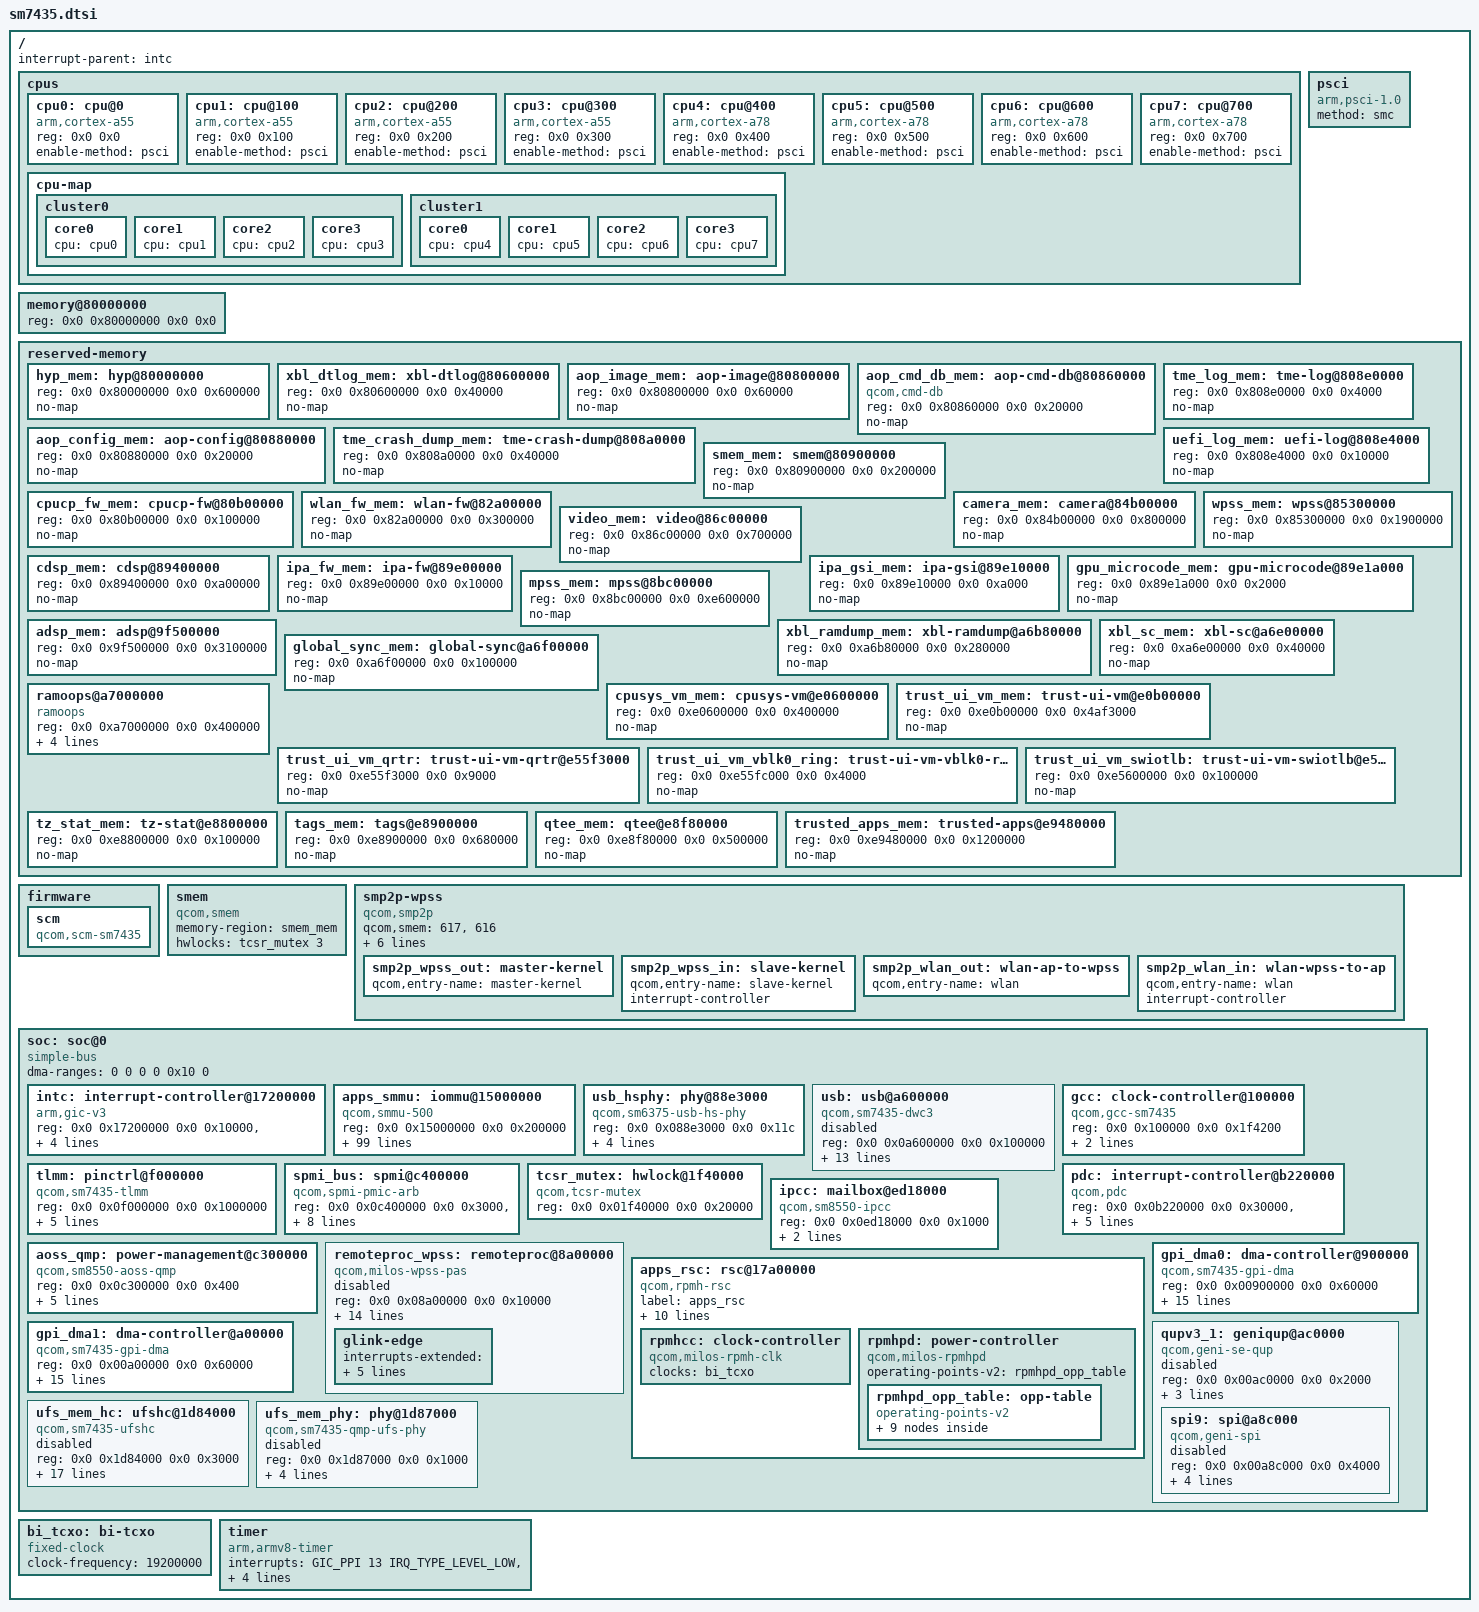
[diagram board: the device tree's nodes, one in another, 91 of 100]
// SPDX-License-Identifier: BSD-3-Clause
/*
 * Qualcomm SM7435 (Snapdragon 7s Gen 2, "parrot") - STAGE 1 skeleton
 *
 * Only what is needed to boot to an initramfs via UEFI:
 * CPUs, PSCI, GICv3, arch timer, reserved memory, ramoops,
 * plus SCM/SMMU, GPI DMA/QUPv3, UFS, USB and SPMI/RPMh (the latter
 * only so that board DTS files can describe PMIC regulators).
 * Values taken from the stock DTB (Mu-Silicium Resources/DTBs/garnet.dts).
 *
 * NOT here yet: display, interconnect, most clocks and pinctrl, ...
 */

#include <dt-bindings/clock/qcom,gcc-sm7435.h>
#include <dt-bindings/clock/qcom,rpmh.h>
#include <dt-bindings/dma/qcom-gpi.h>
#include <dt-bindings/interrupt-controller/arm-gic.h>
#include <dt-bindings/mailbox/qcom-ipcc.h>
#include <dt-bindings/power/qcom,rpmhpd.h>
#include <dt-bindings/soc/qcom,rpmh-rsc.h>

/ {
	interrupt-parent = <&intc>;
	#address-cells = <2>;
	#size-cells = <2>;

	cpus {
		#address-cells = <2>;
		#size-cells = <0>;

		/* 4x Cortex-A55 ("silver") */
		cpu0: cpu@0 {
			device_type = "cpu";
			compatible = "arm,cortex-a55";
			reg = <0x0 0x0>;
			enable-method = "psci";
		};

		cpu1: cpu@100 {
			device_type = "cpu";
			compatible = "arm,cortex-a55";
			reg = <0x0 0x100>;
			enable-method = "psci";
		};

		cpu2: cpu@200 {
			device_type = "cpu";
			compatible = "arm,cortex-a55";
			reg = <0x0 0x200>;
			enable-method = "psci";
		};

		cpu3: cpu@300 {
			device_type = "cpu";
			compatible = "arm,cortex-a55";
			reg = <0x0 0x300>;
			enable-method = "psci";
		};

		/* 4x Cortex-A78 ("gold") */
		cpu4: cpu@400 {
			device_type = "cpu";
			compatible = "arm,cortex-a78";
			reg = <0x0 0x400>;
			enable-method = "psci";
		};

		cpu5: cpu@500 {
			device_type = "cpu";
			compatible = "arm,cortex-a78";
			reg = <0x0 0x500>;
			enable-method = "psci";
		};

		cpu6: cpu@600 {
			device_type = "cpu";
			compatible = "arm,cortex-a78";
			reg = <0x0 0x600>;
			enable-method = "psci";
		};

		cpu7: cpu@700 {
			device_type = "cpu";
			compatible = "arm,cortex-a78";
			reg = <0x0 0x700>;
			enable-method = "psci";
		};

		cpu-map {
			cluster0 {
				core0 { cpu = <&cpu0>; };
				core1 { cpu = <&cpu1>; };
				core2 { cpu = <&cpu2>; };
				core3 { cpu = <&cpu3>; };
			};

			cluster1 {
				core0 { cpu = <&cpu4>; };
				core1 { cpu = <&cpu5>; };
				core2 { cpu = <&cpu6>; };
				core3 { cpu = <&cpu7>; };
			};
		};
	};

	psci {
		compatible = "arm,psci-1.0";
		method = "smc";
	};

	/*
	 * RAM is taken from the UEFI memory map; the stock memory node has
	 * odd, variant-specific ranges. Zero size = ignored by the kernel.
	 */
	memory@80000000 {
		device_type = "memory";
		reg = <0x0 0x80000000 0x0 0x0>;
	};

	reserved-memory {
		#address-cells = <2>;
		#size-cells = <2>;
		ranges;

		hyp_mem: hyp@80000000 {
			reg = <0x0 0x80000000 0x0 0x600000>;
			no-map;
		};

		xbl_dtlog_mem: xbl-dtlog@80600000 {
			reg = <0x0 0x80600000 0x0 0x40000>;
			no-map;
		};

		aop_image_mem: aop-image@80800000 {
			reg = <0x0 0x80800000 0x0 0x60000>;
			no-map;
		};

		aop_cmd_db_mem: aop-cmd-db@80860000 {
			compatible = "qcom,cmd-db";
			reg = <0x0 0x80860000 0x0 0x20000>;
			no-map;
		};

		aop_config_mem: aop-config@80880000 {
			reg = <0x0 0x80880000 0x0 0x20000>;
			no-map;
		};

		tme_crash_dump_mem: tme-crash-dump@808a0000 {
			reg = <0x0 0x808a0000 0x0 0x40000>;
			no-map;
		};

		tme_log_mem: tme-log@808e0000 {
			reg = <0x0 0x808e0000 0x0 0x4000>;
			no-map;
		};

		uefi_log_mem: uefi-log@808e4000 {
			reg = <0x0 0x808e4000 0x0 0x10000>;
			no-map;
		};

		smem_mem: smem@80900000 {
			reg = <0x0 0x80900000 0x0 0x200000>;
			no-map;
		};

		cpucp_fw_mem: cpucp-fw@80b00000 {
			reg = <0x0 0x80b00000 0x0 0x100000>;
			no-map;
		};

		wlan_fw_mem: wlan-fw@82a00000 {
			reg = <0x0 0x82a00000 0x0 0x300000>;
			no-map;
		};

		camera_mem: camera@84b00000 {
			reg = <0x0 0x84b00000 0x0 0x800000>;
			no-map;
		};

		wpss_mem: wpss@85300000 {
			reg = <0x0 0x85300000 0x0 0x1900000>;
			no-map;
		};

		video_mem: video@86c00000 {
			reg = <0x0 0x86c00000 0x0 0x700000>;
			no-map;
		};

		cdsp_mem: cdsp@89400000 {
			reg = <0x0 0x89400000 0x0 0xa00000>;
			no-map;
		};

		ipa_fw_mem: ipa-fw@89e00000 {
			reg = <0x0 0x89e00000 0x0 0x10000>;
			no-map;
		};

		ipa_gsi_mem: ipa-gsi@89e10000 {
			reg = <0x0 0x89e10000 0x0 0xa000>;
			no-map;
		};

		gpu_microcode_mem: gpu-microcode@89e1a000 {
			reg = <0x0 0x89e1a000 0x0 0x2000>;
			no-map;
		};

		mpss_mem: mpss@8bc00000 {
			reg = <0x0 0x8bc00000 0x0 0xe600000>;
			no-map;
		};

		adsp_mem: adsp@9f500000 {
			reg = <0x0 0x9f500000 0x0 0x3100000>;
			no-map;
		};

		xbl_ramdump_mem: xbl-ramdump@a6b80000 {
			reg = <0x0 0xa6b80000 0x0 0x280000>;
			no-map;
		};

		xbl_sc_mem: xbl-sc@a6e00000 {
			reg = <0x0 0xa6e00000 0x0 0x40000>;
			no-map;
		};

		global_sync_mem: global-sync@a6f00000 {
			reg = <0x0 0xa6f00000 0x0 0x100000>;
			no-map;
		};

		/* Debug: survives reboot, read via /sys/fs/pstore */
		ramoops@a7000000 {
			compatible = "ramoops";
			reg = <0x0 0xa7000000 0x0 0x400000>;
			record-size = <0x40000>;
			console-size = <0x200000>;
			pmsg-size = <0x100000>;
			no-map;
		};

		/*
		 * cont_splash 0xb8000000 (0x2b00000) is intentionally NOT listed:
		 * the UEFI GOP framebuffer lives around there and the EFI stub
		 * + simpledrm handle it from the EFI memory map.
		 */

		cpusys_vm_mem: cpusys-vm@e0600000 {
			reg = <0x0 0xe0600000 0x0 0x400000>;
			no-map;
		};

		trust_ui_vm_mem: trust-ui-vm@e0b00000 {
			reg = <0x0 0xe0b00000 0x0 0x4af3000>;
			no-map;
		};

		trust_ui_vm_qrtr: trust-ui-vm-qrtr@e55f3000 {
			reg = <0x0 0xe55f3000 0x0 0x9000>;
			no-map;
		};

		trust_ui_vm_vblk0_ring: trust-ui-vm-vblk0-ring@e55fc000 {
			reg = <0x0 0xe55fc000 0x0 0x4000>;
			no-map;
		};

		trust_ui_vm_swiotlb: trust-ui-vm-swiotlb@e5600000 {
			reg = <0x0 0xe5600000 0x0 0x100000>;
			no-map;
		};

		tz_stat_mem: tz-stat@e8800000 {
			reg = <0x0 0xe8800000 0x0 0x100000>;
			no-map;
		};

		tags_mem: tags@e8900000 {
			reg = <0x0 0xe8900000 0x0 0x680000>;
			no-map;
		};

		qtee_mem: qtee@e8f80000 {
			reg = <0x0 0xe8f80000 0x0 0x500000>;
			no-map;
		};

		trusted_apps_mem: trusted-apps@e9480000 {
			reg = <0x0 0xe9480000 0x0 0x1200000>;
			no-map;
		};
	};

	/*
	 * Secure Channel Manager.  arm-smmu-qcom refuses to finish probing
	 * until qcom_scm_is_available() is true, so without this node the
	 * apps SMMU stays in -EPROBE_DEFER forever and every master that
	 * references it (GPI DMA, QUPv3, UFS, USB) defers as well.
	 * Stock: firmware/qcom_scm, compatible "qcom,scm-v1.1", "qcom,scm".
	 */
	firmware {
		scm: scm {
			compatible = "qcom,scm-sm7435", "qcom,scm";
			#reset-cells = <1>;
		};
	};

	smem {
		compatible = "qcom,smem";
		memory-region = <&smem_mem>;
		hwlocks = <&tcsr_mutex 3>;
	};

	smp2p-wpss {
		compatible = "qcom,smp2p";
		qcom,smem = <617>, <616>;
		interrupts-extended = <&ipcc IPCC_CLIENT_WPSS
					     IPCC_MPROC_SIGNAL_SMP2P
					     IRQ_TYPE_EDGE_RISING>;
		mboxes = <&ipcc IPCC_CLIENT_WPSS IPCC_MPROC_SIGNAL_SMP2P>;

		qcom,local-pid = <0>;
		qcom,remote-pid = <13>;

		smp2p_wpss_out: master-kernel {
			qcom,entry-name = "master-kernel";
			#qcom,smem-state-cells = <1>;
		};

		smp2p_wpss_in: slave-kernel {
			qcom,entry-name = "slave-kernel";
			interrupt-controller;
			#interrupt-cells = <2>;
		};

		/* WLAN handshake with the WPSS-hosted WiFi firmware */
		smp2p_wlan_out: wlan-ap-to-wpss {
			qcom,entry-name = "wlan";
			#qcom,smem-state-cells = <1>;
		};

		smp2p_wlan_in: wlan-wpss-to-ap {
			qcom,entry-name = "wlan";
			interrupt-controller;
			#interrupt-cells = <2>;
		};
	};

	soc: soc@0 {
		compatible = "simple-bus";
		#address-cells = <2>;
		#size-cells = <2>;
		ranges = <0 0 0 0 0x10 0>;
		dma-ranges = <0 0 0 0 0x10 0>;

		intc: interrupt-controller@17200000 {
			compatible = "arm,gic-v3";
			reg = <0x0 0x17200000 0x0 0x10000>,	/* GICD */
			      <0x0 0x17260000 0x0 0x100000>;	/* GICR * 8 */
			#interrupt-cells = <3>;
			interrupt-controller;
			#redistributor-regions = <1>;
			interrupts = <GIC_PPI 9 IRQ_TYPE_LEVEL_LOW>;
		};

		/*
		 * Applications SMMU (ARM MMU-500 with Qualcomm glue).
		 *
		 * The APPS SMMU is left enabled by the bootloader, so every bus
		 * master that is not described here is subject to whatever
		 * translation state the firmware programmed.  Linux must own the
		 * SMMU so that the DMA masters it drives are mapped explicitly;
		 * otherwise the first GPI DMA transaction (SPI9 / touchscreen)
		 * takes an SMMU fault and the SoC resets into crashdump/EDL.
		 *
		 * 0x15000000..0x151fffff covers GR0/GR1, the context banks
		 * (0x15100000+) and the TCU (0x151da000).
		 *
		 * NOTE: this kernel is built with
		 * CONFIG_ARM_SMMU_DISABLE_BYPASS_BY_DEFAULT=y, so streams that
		 * are not described via "iommus" are blocked with a global fault
		 * instead of being bypassed.  Every master that can do DMA must
		 * therefore either be listed here (GPI DMA 0/1, QUPv3 1, UFS,
		 * USB) or keep the "arm-smmu.disable_bypass=0" cmdline option.
		 */
		apps_smmu: iommu@15000000 {
			compatible = "qcom,smmu-500", "arm,mmu-500";
			reg = <0x0 0x15000000 0x0 0x200000>;
			#global-interrupts = <1>;
			#iommu-cells = <2>;
			dma-coherent;
			interrupts = 			     <GIC_SPI 65 IRQ_TYPE_LEVEL_HIGH>,
			     <GIC_SPI 96 IRQ_TYPE_LEVEL_HIGH>,
			     <GIC_SPI 670 IRQ_TYPE_LEVEL_HIGH>,
			     <GIC_SPI 671 IRQ_TYPE_LEVEL_HIGH>,
			     <GIC_SPI 97 IRQ_TYPE_LEVEL_HIGH>,
			     <GIC_SPI 98 IRQ_TYPE_LEVEL_HIGH>,
			     <GIC_SPI 99 IRQ_TYPE_LEVEL_HIGH>,
			     <GIC_SPI 100 IRQ_TYPE_LEVEL_HIGH>,
			     <GIC_SPI 101 IRQ_TYPE_LEVEL_HIGH>,
			     <GIC_SPI 102 IRQ_TYPE_LEVEL_HIGH>,
			     <GIC_SPI 103 IRQ_TYPE_LEVEL_HIGH>,
			     <GIC_SPI 104 IRQ_TYPE_LEVEL_HIGH>,
			     <GIC_SPI 105 IRQ_TYPE_LEVEL_HIGH>,
			     <GIC_SPI 106 IRQ_TYPE_LEVEL_HIGH>,
			     <GIC_SPI 107 IRQ_TYPE_LEVEL_HIGH>,
			     <GIC_SPI 108 IRQ_TYPE_LEVEL_HIGH>,
			     <GIC_SPI 109 IRQ_TYPE_LEVEL_HIGH>,
			     <GIC_SPI 110 IRQ_TYPE_LEVEL_HIGH>,
			     <GIC_SPI 111 IRQ_TYPE_LEVEL_HIGH>,
			     <GIC_SPI 112 IRQ_TYPE_LEVEL_HIGH>,
			     <GIC_SPI 113 IRQ_TYPE_LEVEL_HIGH>,
			     <GIC_SPI 114 IRQ_TYPE_LEVEL_HIGH>,
			     <GIC_SPI 115 IRQ_TYPE_LEVEL_HIGH>,
			     <GIC_SPI 116 IRQ_TYPE_LEVEL_HIGH>,
			     <GIC_SPI 117 IRQ_TYPE_LEVEL_HIGH>,
			     <GIC_SPI 118 IRQ_TYPE_LEVEL_HIGH>,
			     <GIC_SPI 181 IRQ_TYPE_LEVEL_HIGH>,
			     <GIC_SPI 182 IRQ_TYPE_LEVEL_HIGH>,
			     <GIC_SPI 183 IRQ_TYPE_LEVEL_HIGH>,
			     <GIC_SPI 184 IRQ_TYPE_LEVEL_HIGH>,
			     <GIC_SPI 185 IRQ_TYPE_LEVEL_HIGH>,
			     <GIC_SPI 186 IRQ_TYPE_LEVEL_HIGH>,
			     <GIC_SPI 187 IRQ_TYPE_LEVEL_HIGH>,
			     <GIC_SPI 188 IRQ_TYPE_LEVEL_HIGH>,
			     <GIC_SPI 189 IRQ_TYPE_LEVEL_HIGH>,
			     <GIC_SPI 190 IRQ_TYPE_LEVEL_HIGH>,
			     <GIC_SPI 191 IRQ_TYPE_LEVEL_HIGH>,
			     <GIC_SPI 192 IRQ_TYPE_LEVEL_HIGH>,
			     <GIC_SPI 315 IRQ_TYPE_LEVEL_HIGH>,
			     <GIC_SPI 316 IRQ_TYPE_LEVEL_HIGH>,
			     <GIC_SPI 317 IRQ_TYPE_LEVEL_HIGH>,
			     <GIC_SPI 318 IRQ_TYPE_LEVEL_HIGH>,
			     <GIC_SPI 319 IRQ_TYPE_LEVEL_HIGH>,
			     <GIC_SPI 320 IRQ_TYPE_LEVEL_HIGH>,
			     <GIC_SPI 321 IRQ_TYPE_LEVEL_HIGH>,
			     <GIC_SPI 322 IRQ_TYPE_LEVEL_HIGH>,
			     <GIC_SPI 323 IRQ_TYPE_LEVEL_HIGH>,
			     <GIC_SPI 324 IRQ_TYPE_LEVEL_HIGH>,
			     <GIC_SPI 325 IRQ_TYPE_LEVEL_HIGH>,
			     <GIC_SPI 326 IRQ_TYPE_LEVEL_HIGH>,
			     <GIC_SPI 327 IRQ_TYPE_LEVEL_HIGH>,
			     <GIC_SPI 328 IRQ_TYPE_LEVEL_HIGH>,
			     <GIC_SPI 329 IRQ_TYPE_LEVEL_HIGH>,
			     <GIC_SPI 330 IRQ_TYPE_LEVEL_HIGH>,
			     <GIC_SPI 331 IRQ_TYPE_LEVEL_HIGH>,
			     <GIC_SPI 332 IRQ_TYPE_LEVEL_HIGH>,
			     <GIC_SPI 333 IRQ_TYPE_LEVEL_HIGH>,
			     <GIC_SPI 334 IRQ_TYPE_LEVEL_HIGH>,
			     <GIC_SPI 335 IRQ_TYPE_LEVEL_HIGH>,
			     <GIC_SPI 336 IRQ_TYPE_LEVEL_HIGH>,
			     <GIC_SPI 337 IRQ_TYPE_LEVEL_HIGH>,
			     <GIC_SPI 338 IRQ_TYPE_LEVEL_HIGH>,
			     <GIC_SPI 339 IRQ_TYPE_LEVEL_HIGH>,
			     <GIC_SPI 340 IRQ_TYPE_LEVEL_HIGH>,
			     <GIC_SPI 341 IRQ_TYPE_LEVEL_HIGH>,
			     <GIC_SPI 342 IRQ_TYPE_LEVEL_HIGH>,
			     <GIC_SPI 343 IRQ_TYPE_LEVEL_HIGH>,
			     <GIC_SPI 344 IRQ_TYPE_LEVEL_HIGH>,
			     <GIC_SPI 345 IRQ_TYPE_LEVEL_HIGH>,
			     <GIC_SPI 395 IRQ_TYPE_LEVEL_HIGH>,
			     <GIC_SPI 396 IRQ_TYPE_LEVEL_HIGH>,
			     <GIC_SPI 397 IRQ_TYPE_LEVEL_HIGH>,
			     <GIC_SPI 398 IRQ_TYPE_LEVEL_HIGH>,
			     <GIC_SPI 399 IRQ_TYPE_LEVEL_HIGH>,
			     <GIC_SPI 400 IRQ_TYPE_LEVEL_HIGH>,
			     <GIC_SPI 401 IRQ_TYPE_LEVEL_HIGH>,
			     <GIC_SPI 402 IRQ_TYPE_LEVEL_HIGH>,
			     <GIC_SPI 403 IRQ_TYPE_LEVEL_HIGH>,
			     <GIC_SPI 404 IRQ_TYPE_LEVEL_HIGH>,
			     <GIC_SPI 405 IRQ_TYPE_LEVEL_HIGH>,
			     <GIC_SPI 406 IRQ_TYPE_LEVEL_HIGH>,
			     <GIC_SPI 407 IRQ_TYPE_LEVEL_HIGH>,
			     <GIC_SPI 408 IRQ_TYPE_LEVEL_HIGH>,
			     <GIC_SPI 409 IRQ_TYPE_LEVEL_HIGH>,
			     <GIC_SPI 412 IRQ_TYPE_LEVEL_HIGH>,
			     <GIC_SPI 418 IRQ_TYPE_LEVEL_HIGH>,
			     <GIC_SPI 419 IRQ_TYPE_LEVEL_HIGH>,
			     <GIC_SPI 421 IRQ_TYPE_LEVEL_HIGH>,
			     <GIC_SPI 706 IRQ_TYPE_LEVEL_HIGH>,
			     <GIC_SPI 423 IRQ_TYPE_LEVEL_HIGH>,
			     <GIC_SPI 424 IRQ_TYPE_LEVEL_HIGH>,
			     <GIC_SPI 425 IRQ_TYPE_LEVEL_HIGH>,
			     <GIC_SPI 689 IRQ_TYPE_LEVEL_HIGH>,
			     <GIC_SPI 690 IRQ_TYPE_LEVEL_HIGH>,
			     <GIC_SPI 691 IRQ_TYPE_LEVEL_HIGH>,
			     <GIC_SPI 692 IRQ_TYPE_LEVEL_HIGH>,
			     <GIC_SPI 693 IRQ_TYPE_LEVEL_HIGH>;
		};


		/*
		 * USB (stage 2a, EXPERIMENTAL): dwc3 + Qualcomm glue, relying on the
		 * clocks, GDSC and HS PHY that Mu-Silicium UEFI already brought up
		 * (boot with clk_ignore_unused pd_ignore_unused). No GCC/PHY/regulator
		 * drivers exist for this SoC yet, so none are referenced here.
		 * Stock node: ssusb@a600000 (core 0xa600000, qscratch = +0xf8800).
		 */
		/*
		 * HS (femto) PHY, stock hsphy@88e3000.  The supplies (stock:
		 * vdd 0.88 V, vdda18, vdda33) are not described yet: the rails
		 * stay as the bootloader left them.
		 */
		usb_hsphy: phy@88e3000 {
			compatible = "qcom,sm6375-usb-hs-phy",
				     "qcom,usb-snps-hs-7nm-phy";
			reg = <0x0 0x088e3000 0x0 0x11c>;

			clocks = <&gcc GCC_EUSB3_0_CLKREF_EN>;
			clock-names = "ref";
			resets = <&gcc GCC_QUSB2PHY_PRIM_BCR>;

			/* stock qcom,param-override-seq: <value offset> pairs */
			qcom,param-override-seq = <0x67 0x6c 0xcb 0x70 0x14 0x74>;

			#phy-cells = <0>;
		};

		usb: usb@a600000 {
			compatible = "qcom,sm7435-dwc3", "qcom,snps-dwc3";
			reg = <0x0 0x0a600000 0x0 0x100000>;
			interrupts = <GIC_SPI 133 IRQ_TYPE_LEVEL_HIGH>;
			interrupt-names = "dwc_usb3";
			phys = <&usb_hsphy>;
			phy-names = "usb2-phy";
			/* stock: dwc3@a600000 iommus = <&apps_smmu 0x80 0> */
			iommus = <&apps_smmu 0x80 0x0>;
			dma-coherent;

			/*
			 * No phy_type: leave GUSB2PHYCFG.PHYIF/USBTRDTIM at the
			 * hardware default like every other Qualcomm femto-PHY
			 * platform.  Forcing "utmi_wide" is a width mismatch if
			 * the PHY runs 8-bit UTMI+ (reset/chirp still work, data
			 * does not -> -71 on the host).
			 */
			snps,has-lpm-erratum;
			snps,hird-threshold = /bits/ 8 <0x0>;
			snps,is-utmi-l1-suspend;
			snps,usb2-gadget-lpm-disable;
			snps,dis-u1-entry-quirk;
			snps,dis-u2-entry-quirk;
			snps,dis_u2_susphy_quirk;
			snps,dis_u3_susphy_quirk;
			/* stock DT sets this; ep0 DEPCFG times out without it */
			snps,disable-clk-gating;

			status = "disabled";
		};

		/*
		 * Global clock controller (stage 2b).
		 *
		 * Only the clocks needed by the UFS host controller and the QMP
		 * UFS PHY are implemented in drivers/clk/qcom/gcc-sm7435.c so far.
		 * The register offsets are taken from the downstream
		 * "qcom,parrot-gcc" driver.
		 */
		gcc: clock-controller@100000 {
			compatible = "qcom,gcc-sm7435";
			reg = <0x0 0x100000 0x0 0x1f4200>;
			#clock-cells = <1>;
			#reset-cells = <1>;
			#power-domain-cells = <1>;

			clocks = <&bi_tcxo>,
				 <&ufs_mem_phy 0>,
				 <&ufs_mem_phy 1>,
				 <&ufs_mem_phy 2>;
			clock-names = "bi_tcxo",
				      "ufs_phy_rx_symbol_0_clk",
				      "ufs_phy_rx_symbol_1_clk",
				      "ufs_phy_tx_symbol_0_clk";
		};

		tlmm: pinctrl@f000000 {
			compatible = "qcom,sm7435-tlmm";
			reg = <0x0 0x0f000000 0x0 0x1000000>;
			interrupts = <GIC_SPI 208 IRQ_TYPE_LEVEL_HIGH>;
			gpio-controller;
			#gpio-cells = <2>;
			gpio-ranges = <&tlmm 0 0 142>;
			/* TZ owned (fingerprint/secure) lines: 0-3, 38 */
			gpio-reserved-ranges = <0 4>, <38 1>;
			interrupt-controller;
			#interrupt-cells = <2>;
		};

		/*
		 * SPMI bus (PMIC arbiter).  Same register layout as SM8550,
		 * taken from the stock garnet DTB.  Needed for the PM6150L
		 * PMIC GPIOs, which drive the touchscreen's 1.8 V iovdd rail.
		 */
		spmi_bus: spmi@c400000 {
			compatible = "qcom,spmi-pmic-arb";
			reg = <0x0 0x0c400000 0x0 0x3000>,
			      <0x0 0x0c500000 0x0 0x400000>,
			      <0x0 0x0c440000 0x0 0x80000>,
			      <0x0 0x0c4c0000 0x0 0x20000>,
			      <0x0 0x0c42d000 0x0 0x4000>;
			reg-names = "core", "chnls", "obsrvr", "intr", "cnfg";
			interrupt-names = "periph_irq";
			interrupts-extended = <&pdc 1 IRQ_TYPE_LEVEL_HIGH>;
			qcom,ee = <0>;
			qcom,channel = <0>;
			#address-cells = <2>;
			#size-cells = <0>;
			interrupt-controller;
			#interrupt-cells = <4>;
		};

		/*
		 * Wakeup interrupt controller in front of a few GIC SPIs
		 * (SPMI peripheral IRQ, ...).  Values from the stock DTB.
		 */
		pdc: interrupt-controller@b220000 {
			compatible = "qcom,pdc";
			reg = <0x0 0x0b220000 0x0 0x30000>,
			      <0x0 0x174000f0 0x0 0x64>;
			reg-names = "pdc-interrupt-base", "apss-shared-spi-cfg";
			qcom,pdc-ranges = <0 480 94>,
					  <94 609 31>,
					  <125 63 1>,
					  <126 716 12>;
			#interrupt-cells = <2>;
			interrupt-parent = <&intc>;
			interrupt-controller;
		};

		tcsr_mutex: hwlock@1f40000 {
			compatible = "qcom,tcsr-mutex";
			reg = <0x0 0x01f40000 0x0 0x20000>;
			#hwlock-cells = <1>;
		};

		/* stock: qcom,ipcc@ed18000 */
		ipcc: mailbox@ed18000 {
			compatible = "qcom,sm8550-ipcc", "qcom,ipcc";
			reg = <0x0 0x0ed18000 0x0 0x1000>;
			interrupts = <GIC_SPI 229 IRQ_TYPE_LEVEL_HIGH>;
			interrupt-controller;
			#interrupt-cells = <3>;
			#mbox-cells = <2>;
		};

		aoss_qmp: power-management@c300000 {
			compatible = "qcom,sm8550-aoss-qmp", "qcom,aoss-qmp";
			reg = <0x0 0x0c300000 0x0 0x400>;
			interrupt-parent = <&ipcc>;
			interrupts-extended = <&ipcc IPCC_CLIENT_AOP
						     IPCC_MPROC_SIGNAL_GLINK_QMP
						     IRQ_TYPE_EDGE_RISING>;
			mboxes = <&ipcc IPCC_CLIENT_AOP IPCC_MPROC_SIGNAL_GLINK_QMP>;
			#clock-cells = <0>;
		};

		/*
		 * WPSS (Wi-Fi processing subsystem): runs the WiFi firmware.
		 * Stock node: remoteproc-wpss@8a00000, qcom,parrot-wpss-pas.
		 * The PAS data of milos/sc7280 (pas_id 6) is reused.
		 */
		remoteproc_wpss: remoteproc@8a00000 {
			compatible = "qcom,milos-wpss-pas";
			reg = <0x0 0x08a00000 0x0 0x10000>;

			interrupts-extended = <&intc GIC_SPI 587 IRQ_TYPE_EDGE_RISING>,
					      <&smp2p_wpss_in 0 IRQ_TYPE_EDGE_RISING>,
					      <&smp2p_wpss_in 1 IRQ_TYPE_EDGE_RISING>,
					      <&smp2p_wpss_in 2 IRQ_TYPE_EDGE_RISING>,
					      <&smp2p_wpss_in 3 IRQ_TYPE_EDGE_RISING>,
					      <&smp2p_wpss_in 7 IRQ_TYPE_EDGE_RISING>;
			interrupt-names = "wdog",
					  "fatal",
					  "ready",
					  "handover",
					  "stop-ack",
					  "shutdown-ack";

			clocks = <&rpmhcc RPMH_CXO_CLK>;
			clock-names = "xo";

			power-domains = <&rpmhpd RPMHPD_CX>,
					<&rpmhpd RPMHPD_MX>;
			power-domain-names = "cx",
					     "mx";

			memory-region = <&wpss_mem>;

			qcom,qmp = <&aoss_qmp>;

			qcom,smem-states = <&smp2p_wpss_out 0>;
			qcom,smem-state-names = "stop";

			status = "disabled";

			glink-edge {
				interrupts-extended = <&ipcc IPCC_CLIENT_WPSS
							     IPCC_MPROC_SIGNAL_GLINK_QMP
							     IRQ_TYPE_EDGE_RISING>;
				mboxes = <&ipcc IPCC_CLIENT_WPSS
						IPCC_MPROC_SIGNAL_GLINK_QMP>;

				label = "wpss";
				qcom,remote-pid = <13>;
			};
		};

		/*
		 * RPMh (resource power manager, hardened).  Same layout as
		 * SM8550; the regulators used by the board (PM6150L LDOs) are
		 * described as children of this node in the board DTS.
		 */
		apps_rsc: rsc@17a00000 {
			label = "apps_rsc";
			compatible = "qcom,rpmh-rsc";
			reg = <0x0 0x17a00000 0x0 0x10000>,
			      <0x0 0x17a10000 0x0 0x10000>,
			      <0x0 0x17a20000 0x0 0x10000>;
			reg-names = "drv-0", "drv-1", "drv-2";
			interrupts = <GIC_SPI 3 IRQ_TYPE_LEVEL_HIGH>,
				     <GIC_SPI 4 IRQ_TYPE_LEVEL_HIGH>,
				     <GIC_SPI 5 IRQ_TYPE_LEVEL_HIGH>;
			qcom,tcs-offset = <0xd00>;
			qcom,drv-id = <2>;
			qcom,tcs-config = <ACTIVE_TCS 3>, <SLEEP_TCS 2>,
					  <WAKE_TCS 2>, <CONTROL_TCS 0>;

			rpmhcc: clock-controller {
				compatible = "qcom,milos-rpmh-clk";
				clocks = <&bi_tcxo>;
				clock-names = "xo";
				#clock-cells = <1>;
			};

			rpmhpd: power-controller {
				compatible = "qcom,milos-rpmhpd";
				#power-domain-cells = <1>;
				operating-points-v2 = <&rpmhpd_opp_table>;

				rpmhpd_opp_table: opp-table {
					compatible = "operating-points-v2";

					rpmhpd_opp_ret: opp-16 {
						opp-level = <RPMH_REGULATOR_LEVEL_RETENTION>;
					};

					rpmhpd_opp_low_svs_d1: opp-56 {
						opp-level = <RPMH_REGULATOR_LEVEL_LOW_SVS_D1>;
					};

					rpmhpd_opp_low_svs: opp-64 {
						opp-level = <RPMH_REGULATOR_LEVEL_LOW_SVS>;
					};

					rpmhpd_opp_svs: opp-128 {
						opp-level = <RPMH_REGULATOR_LEVEL_SVS>;
					};

					rpmhpd_opp_svs_l1: opp-192 {
						opp-level = <RPMH_REGULATOR_LEVEL_SVS_L1>;
					};

					rpmhpd_opp_nom: opp-256 {
						opp-level = <RPMH_REGULATOR_LEVEL_NOM>;
					};

					rpmhpd_opp_nom_l1: opp-320 {
						opp-level = <RPMH_REGULATOR_LEVEL_NOM_L1>;
					};

					rpmhpd_opp_turbo: opp-384 {
						opp-level = <RPMH_REGULATOR_LEVEL_TURBO>;
					};

					rpmhpd_opp_turbo_l1: opp-416 {
						opp-level = <RPMH_REGULATOR_LEVEL_TURBO_L1>;
					};
				};
			};
		};

		/*
		 * GPI DMA for the QUPv3 serial engines.  The serial engines
		 * have their FIFO interface disabled, so SPI/I2C/UART
		 * transfers must use GPI DMA.
		 *
		 * There is one GPI DMA instance per QUPv3 wrapper and the
		 * instances are *not* interchangeable: the instance at 0x900000
		 * drives the serial engines of wrapper 0 (0x980000..0x9c0000),
		 * the instance at 0xa00000 drives the engines of wrapper 1
		 * (0xa80000..0xac0000).  Pointing an engine at the wrong
		 * instance leaves the DMA descriptors stranded, the engine
		 * never completes the transfer and every SPI transfer ends in
		 * "SPI transfer timed out".
		 *
		 * Stock nodes: qcom,gpi-dma@900000 and @a00000 (12 GPIIs each,
		 * engine end offset 0x10000).  The layout matches the
		 * qcom,sm6350-gpi-dma driver.
		 */
		gpi_dma0: dma-controller@900000 {
			compatible = "qcom,sm7435-gpi-dma", "qcom,sm6350-gpi-dma";
			reg = <0x0 0x00900000 0x0 0x60000>;
			interrupts = <GIC_SPI 244 IRQ_TYPE_LEVEL_HIGH>,
				     <GIC_SPI 245 IRQ_TYPE_LEVEL_HIGH>,
				     <GIC_SPI 246 IRQ_TYPE_LEVEL_HIGH>,
				     <GIC_SPI 247 IRQ_TYPE_LEVEL_HIGH>,
				     <GIC_SPI 248 IRQ_TYPE_LEVEL_HIGH>,
				     <GIC_SPI 249 IRQ_TYPE_LEVEL_HIGH>,
				     <GIC_SPI 250 IRQ_TYPE_LEVEL_HIGH>,
				     <GIC_SPI 251 IRQ_TYPE_LEVEL_HIGH>,
				     <GIC_SPI 252 IRQ_TYPE_LEVEL_HIGH>,
				     <GIC_SPI 253 IRQ_TYPE_LEVEL_HIGH>,
				     <GIC_SPI 254 IRQ_TYPE_LEVEL_HIGH>,
				     <GIC_SPI 255 IRQ_TYPE_LEVEL_HIGH>;
			dma-channels = <12>;
			dma-channel-mask = <0x3f>;
			#dma-cells = <3>;
			/* stock: gpi_dma0 iommus = <&apps_smmu 0x176 0> */
			iommus = <&apps_smmu 0x176 0x0>;
		};

		gpi_dma1: dma-controller@a00000 {
			compatible = "qcom,sm7435-gpi-dma", "qcom,sm6350-gpi-dma";
			reg = <0x0 0x00a00000 0x0 0x60000>;
			interrupts = <GIC_SPI 279 IRQ_TYPE_LEVEL_HIGH>,
				     <GIC_SPI 280 IRQ_TYPE_LEVEL_HIGH>,
				     <GIC_SPI 281 IRQ_TYPE_LEVEL_HIGH>,
				     <GIC_SPI 282 IRQ_TYPE_LEVEL_HIGH>,
				     <GIC_SPI 283 IRQ_TYPE_LEVEL_HIGH>,
				     <GIC_SPI 284 IRQ_TYPE_LEVEL_HIGH>,
				     <GIC_SPI 293 IRQ_TYPE_LEVEL_HIGH>,
				     <GIC_SPI 294 IRQ_TYPE_LEVEL_HIGH>,
				     <GIC_SPI 295 IRQ_TYPE_LEVEL_HIGH>,
				     <GIC_SPI 296 IRQ_TYPE_LEVEL_HIGH>,
				     <GIC_SPI 297 IRQ_TYPE_LEVEL_HIGH>,
				     <GIC_SPI 298 IRQ_TYPE_LEVEL_HIGH>;
			dma-channels = <12>;
			/* GPII 0 is statically assigned on this SoC */
			dma-channel-mask = <0x3e>;
			#dma-cells = <3>;
			/*
			 * Stream IDs from the stock device tree.  Without these
			 * the GPI engine DMA's with untranslated physical
			 * addresses while the SMMU is configured for this
			 * master, which aborts the transfer and resets the SoC.
			 */
			iommus = <&apps_smmu 0x416 0x0>;
		};

		/* QUPv3 wrapper 1 (serial engines 6..11 in downstream naming) */
		qupv3_1: geniqup@ac0000 {
			compatible = "qcom,geni-se-qup";
			reg = <0x0 0x00ac0000 0x0 0x2000>;
			clocks = <&gcc GCC_QUPV3_WRAP_1_M_AHB_CLK>,
				 <&gcc GCC_QUPV3_WRAP_1_S_AHB_CLK>;
			clock-names = "m-ahb", "s-ahb";
			#address-cells = <2>;
			#size-cells = <2>;
			/* stock: qupv3_1_geni_se iommus = <&apps_smmu 0x403 0x0> */
			iommus = <&apps_smmu 0x403 0x0>;
			ranges;
			status = "disabled";

			/* wrapper 1 SE3 (downstream: qupv3_se9_spi) */
			spi9: spi@a8c000 {
				compatible = "qcom,geni-spi";
				reg = <0x0 0x00a8c000 0x0 0x4000>;
				interrupts = <GIC_SPI 356 IRQ_TYPE_LEVEL_HIGH>;
				clocks = <&gcc GCC_QUPV3_WRAP1_S3_CLK>;
				clock-names = "se";
				#address-cells = <1>;
				#size-cells = <0>;
				dmas = <&gpi_dma1 0 3 QCOM_GPI_SPI>,
				       <&gpi_dma1 1 3 QCOM_GPI_SPI>;
				dma-names = "tx", "rx";
				status = "disabled";
			};
		};

		/*
		 * UFS host controller (stage 2b).
		 *
		 * Stock node: ufshc@1d84000 (core 0x1d84000, ICE 0x1d88000,
		 * ICE hwkm 0x1d90000), interrupt 265.
		 */
		ufs_mem_hc: ufshc@1d84000 {
			compatible = "qcom,sm7435-ufshc", "qcom,ufshc",
				     "jedec,ufs-2.0";
			reg = <0x0 0x1d84000 0x0 0x3000>;
			interrupts = <GIC_SPI 265 IRQ_TYPE_LEVEL_HIGH>;

			phys = <&ufs_mem_phy>;
			phy-names = "ufsphy";
			lanes-per-direction = <2>;

			/* The UFS PHY is reset through the host controller. */
			#reset-cells = <1>;
			resets = <&gcc GCC_UFS_PHY_BCR>;
			reset-names = "rst";

			power-domains = <&gcc UFS_PHY_GDSC>;

			clock-names =
				"core_clk",
				"bus_aggr_clk",
				"iface_clk",
				"core_clk_unipro",
				"ref_clk",
				"tx_lane0_sync_clk",
				"rx_lane0_sync_clk",
				"rx_lane1_sync_clk";
			clocks =
				<&gcc GCC_UFS_PHY_AXI_CLK>,
				<&gcc GCC_AGGRE_UFS_PHY_AXI_CLK>,
				<&gcc GCC_UFS_PHY_AHB_CLK>,
				<&gcc GCC_UFS_PHY_UNIPRO_CORE_CLK>,
				<&bi_tcxo>,
				<&gcc GCC_UFS_PHY_TX_SYMBOL_0_CLK>,
				<&gcc GCC_UFS_PHY_RX_SYMBOL_0_CLK>,
				<&gcc GCC_UFS_PHY_RX_SYMBOL_1_CLK>;
			freq-table-hz =
				<75000000 300000000>,
				<0 0>,
				<0 0>,
				<75000000 300000000>,
				/* ref_clk is a fixed 19.2 MHz clock, do not reprogram it */
				<0 0>,
				<0 0>,
				<0 0>,
				<0 0>;

			/* 19.2 MHz reference clock for the host and the device */
			ref-clk-freq = <19200000>;

			/*
			 * Stream ID from the stock device tree.  This kernel is
			 * built with CONFIG_ARM_SMMU_DISABLE_BYPASS_BY_DEFAULT,
			 * so an unlisted master would be blocked with a global
			 * fault instead of being bypassed: every active DMA
			 * master must be attached.
			 */
			iommus = <&apps_smmu 0x20 0x0>;
			dma-coherent;

			status = "disabled";
		};

		/*
		 * QMP UFS PHY (stage 2b).
		 *
		 * Stock node: ufsphy_mem@1d87000, "qcom,ufs-phy-qmp-v4-parrot".
		 * The symbol clocks exported by this node are the parents of
		 * the GCC symbol clock multiplexers.
		 */
		ufs_mem_phy: phy@1d87000 {
			compatible = "qcom,sm7435-qmp-ufs-phy";
			reg = <0x0 0x1d87000 0x0 0x1000>;

			clock-names = "ref", "ref_aux", "qref";
			clocks = <&bi_tcxo>,
				 <&gcc GCC_UFS_PHY_PHY_AUX_CLK>,
				 <&gcc GCC_UFS_0_CLKREF_EN>;

			power-domains = <&gcc UFS_PHY_GDSC>;

			resets = <&ufs_mem_hc 0>;
			reset-names = "ufsphy";

			#clock-cells = <1>;
			#phy-cells = <0>;

			status = "disabled";
		};
	};

	/*
	 * 19.2 MHz TCXO.  On the SM7435 this clock is provided by the RPMh
	 * subsystem ("bi_tcxo" in the stock device tree); there is no RPMh
	 * clock driver in this kernel yet, so it is described as a fixed
	 * clock.  Replace it with the RPMh clock once that is ported.
	 */
	bi_tcxo: bi-tcxo {
		compatible = "fixed-clock";
		#clock-cells = <0>;
		clock-frequency = <19200000>;
	};

	timer {
		compatible = "arm,armv8-timer";
		interrupts = <GIC_PPI 13 IRQ_TYPE_LEVEL_LOW>,
			     <GIC_PPI 14 IRQ_TYPE_LEVEL_LOW>,
			     <GIC_PPI 11 IRQ_TYPE_LEVEL_LOW>,
			     <GIC_PPI 12 IRQ_TYPE_LEVEL_LOW>;
		always-on;
	};
};
